# STM32WBA54 register map
File version: 1.0
CPU: CM33 r0p1, little endian, MPU, FPU, 4 interrupt priority bits
Registers are 32-bit, read-write, reset 0x0 unless marked. A register's access mark holds for its fields unless they carry their own. Offsets are from the block's base; [hi:lo] are bit positions.

## CRC — CRC register block
Base 0x40023000
Same registers: SEC_CRC 0x50023000
0x00 DR reset 0xFFFFFFFF — CRC data register
  [31:0] DR — Data register bits This register is used to write new data to the CRC calculator. It holds the previous CRC calculation result when it is read. If the data size is less than 32 bits, the least significant bits are used to write/read the correct value.
0x00 DR8 8-bit reset 0xFF (alternate view of DR) — Data register - byte sized
  [7:0] DR8 — Data register bits
0x00 DR16 16-bit reset 0xFFFF (alternate view of DR) — Data register - half-word sized
  [15:0] DR16 — Data register bits
0x04 IDR — CRC independent data register
  [31:0] IDR — General-purpose 32-bit data register bits These bits can be used as a temporary storage location for four bytes. This register is not affected by CRC resets generated by the RESET bit in the CRC_CR register
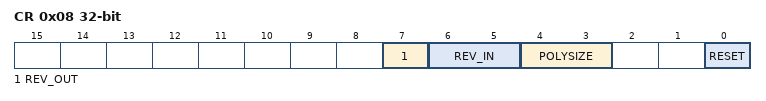
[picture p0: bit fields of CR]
0x08 CR — CRC control register
  [7] REV_OUT — Reverse output data This bit controls the reversal of the bit order of the output data.
    0=Normal (Bit order not affected); 1=Reversed (Bit reversed output)
  [6:5] REV_IN — Reverse input data These bits control the reversal of the bit order of the input data
    0=Normal (Bit order not affected); 1=Byte (Bit reversal done by byte); 2=HalfWord (Bit reversal done by half-word); 3=Word (Bit reversal done by word)
  [4:3] POLYSIZE — Polynomial size These bits control the size of the polynomial.
    0=32-bit polynomial; 1=16-bit polynomial; 2=8-bit polynomial; 3=7-bit polynomial
  [0] RESET — RESET bit This bit is set by software to reset the CRC calculation unit and set the data register to the value stored in the CRC_INIT register. This bit can only be set, it is automatically cleared by hardware
    on write: 1=Resets the CRC calculation unit and sets the data register to 0xFFFF FFFF
0x10 INIT reset 0xFFFFFFFF — CRC initial value
  [31:0] INIT — Programmable initial CRC value This register is used to write the CRC initial value.
0x14 POL reset 0x4C11DB7 — CRC polynomial
  [31:0] POL — Programmable polynomial This register is used to write the coefficients of the polynomial to be used for CRC calculation. If the polynomial size is less than 32 bits, the least significant bits have to be used to program the correct value.

## COMP — Comparator
Base 0x46005400
Same registers: SEC_COMP 0x56005400
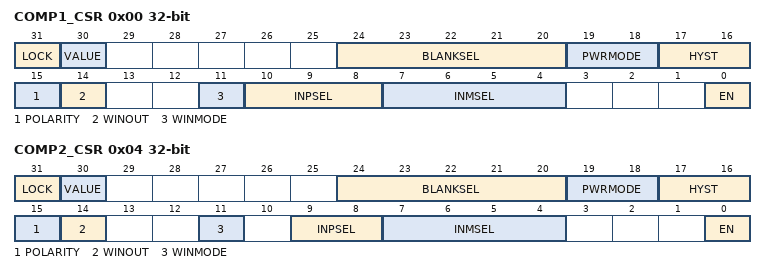
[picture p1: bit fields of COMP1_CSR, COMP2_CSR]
0x00 COMP1_CSR — COMP1 control and status register
  [31] LOCK — COMP1_CSR register lock.
  [30] VALUE ro — COMP1 output status.
  [24:20] BLANKSEL — COMP1 blanking source selector.
  [19:18] PWRMODE — COMP1 power mode selector Controlled by software (if not locked), selects the power consumption and, as a consequence, the speed of the COMP1.
  [17:16] HYST — COMP1 hysteresis selector Controlled by software (if not locked), selects the COMP1 hysteresis.
  [15] POLARITY — COMP1 polarity selector Controlled by software (if not locked), selects the COMP1 output polarity
  [14] WINOUT — COMP1 output selector Controlled by software (if not locked), selects the COMP1 output.
  [11] WINMODE — COMP1 noninverting input selector for window mode Controlled by software (if not locked), selects the signal for the COMP1_INP input of the COMP1.
  [10:8] INPSEL — COMP1 signal selector for inverting input INM Controlled by software (if not locked), selects the signal for the inverting input COMP1_INM
  [7:4] INMSEL — COMP1 signal selector for inverting input INM Controlled by software (if not locked), selects the signal for the inverting input COMP1_INM
  [0] EN — COMP1 enable
0x04 COMP2_CSR — COMP2 control and status register
  [31] LOCK — COMP1_CSR register lock.
  [30] VALUE ro — COMP1 output status.
  [24:20] BLANKSEL — COMP1 blanking source selector.
  [19:18] PWRMODE — COMP1 power mode selector Controlled by software (if not locked), selects the power consumption and, as a consequence, the speed of the COMP1.
  [17:16] HYST — COMP1 hysteresis selector Controlled by software (if not locked), selects the COMP1 hysteresis.
  [15] POLARITY — COMP1 polarity selector Controlled by software (if not locked), selects the COMP1 output polarity
  [14] WINOUT — COMP1 output selector Controlled by software (if not locked), selects the COMP1 output.
  [11] WINMODE — COMP1 noninverting input selector for window mode Controlled by software (if not locked), selects the signal for the COMP1_INP input of the COMP1.
  [9:8] INPSEL — COMP1 signal selector for inverting input INM Controlled by software (if not locked), selects the signal for the inverting input COMP1_INM
  [7:4] INMSEL — COMP1 signal selector for inverting input INM Controlled by software (if not locked), selects the signal for the inverting input COMP1_INM
  [0] EN — COMP1 enable
